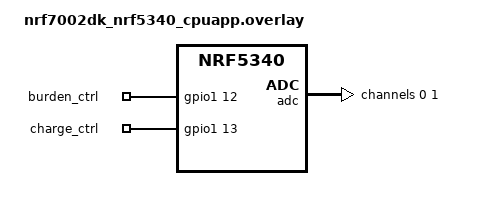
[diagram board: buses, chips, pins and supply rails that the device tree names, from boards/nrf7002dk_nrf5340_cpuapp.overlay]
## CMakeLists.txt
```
#
# Copyright (c) 2021 Nordic Semiconductor ASA
#
# SPDX-License-Identifier: LicenseRef-Nordic-5-Clause
#

cmake_minimum_required(VERSION 3.20.0)

# Set Kconfig root files that will be processed as a first Kconfig for used child images.
set(mcuboot_KCONFIG_ROOT "\\\${ZEPHYR_CONNECTEDHOMEIP_MODULE_DIR}/config/nrfconnect/chip-module/Kconfig.mcuboot.root")
set(multiprotocol_rpmsg_KCONFIG_ROOT "\\\${ZEPHYR_CONNECTEDHOMEIP_MODULE_DIR}/config/nrfconnect/chip-module/Kconfig.multiprotocol_rpmsg.root")
set(hci_rpmsg_KCONFIG_ROOT "\\\${ZEPHYR_CONNECTEDHOMEIP_MODULE_DIR}/config/nrfconnect/chip-module/Kconfig.hci_rpmsg.root")

# For prj.conf the CONF_FILE is empty. In other case extract the exact file name from the path string.
if(CONF_FILE)
    get_filename_component(CONFIG_FILE_NAME ${CONF_FILE} NAME)
endif()

if(NOT "${CONFIG_FILE_NAME}" STREQUAL "prj_no_dfu.conf")
    set(PM_STATIC_YML_FILE ${CMAKE_CURRENT_SOURCE_DIR}/configuration/${BOARD}/pm_static_dfu.yml)
endif()

find_package(Zephyr HINTS $ENV{ZEPHYR_BASE})

project(matter-template)

set(COMMON_ROOT ${ZEPHYR_NRF_MODULE_DIR}/samples/matter/common)
set(NLIO_ROOT ${ZEPHYR_CONNECTEDHOMEIP_MODULE_DIR}/third_party/nlio/repo)
include(${ZEPHYR_CONNECTEDHOMEIP_MODULE_DIR}/config/nrfconnect/app/enable-gnu-std.cmake)
include(${ZEPHYR_CONNECTEDHOMEIP_MODULE_DIR}/src/app/chip_data_model.cmake)

# NORDIC SDK APP START
target_include_directories(app PRIVATE
    src
    ${COMMON_ROOT}/src
    ${NLIO_ROOT}/include
    ${ZEPHYR_CONNECTEDHOMEIP_MODULE_DIR}/zzz_generated/app-common
)

target_sources(app PRIVATE
    src/app_task.cpp
    src/main.cpp
    src/adc.cpp
    src/burden_ctrl.cpp
    src/zcl_callbacks.cpp
    src/zap-generated/IMClusterCommandHandler.cpp
    src/zap-generated/callback-stub.cpp
    ${COMMON_ROOT}/src/led_widget.cpp
)

if(CONFIG_CHIP_OTA_REQUESTOR)
    target_sources(app PRIVATE ${COMMON_ROOT}/src/ota_util.cpp)
endif()

chip_configure_data_model(app
    INCLUDE_SERVER
    BYPASS_IDL
    GEN_DIR src/zap-generated
    ZAP_FILE ${CMAKE_CURRENT_SOURCE_DIR}/src/template.zap
)
# NORDIC SDK APP END
```

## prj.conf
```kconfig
# CPP
CONFIG_STD_CPP14=y

# Reduce application size
CONFIG_USE_SEGGER_RTT=n

# Add support for LEDs and buttons on Nordic development kits
CONFIG_DK_LIBRARY=y
CONFIG_PM_DEVICE=y

# GPIO support
CONFIG_GPIO=y
CONFIG_ADC=y

# Bluetooth Low Energy configuration
CONFIG_BT_DEVICE_NAME="MatterPwrSen"

# Other settings
CONFIG_MPU_STACK_GUARD=y
CONFIG_RESET_ON_FATAL_ERROR=n

# Disable NFC commissioning
CONFIG_CHIP_NFC_COMMISSIONING=n

# Enable Factory Data feature
CONFIG_CHIP_FACTORY_DATA=y
CONFIG_CHIP_FACTORY_DATA_BUILD=y

# Use Thread and Matter
CONFIG_THREAD_NAME=y
CONFIG_CHIP=y
CONFIG_CHIP_ENABLE_PAIRING_AUTOSTART=y
CONFIG_CHIP_PROJECT_CONFIG="src/chip_project_config.h"
CONFIG_CHIP_WIFI=n
CONFIG_ADD_MCUBOOT_MEDIATE_SIM_FLASH_DTS=y
CONFIG_OPENTHREAD_MTD_SED=y
CONFIG_OPENTHREAD_POLL_PERIOD=300000
CONFIG_NRF_CC3XX_PLATFORM=y
CONFIG_CHIP_PERSISTENT_SUBSCRIPTIONS=y
CONFIG_MATTER_LOG_LEVEL_INF=y
CONFIG_CHIP_LAST_FABRIC_REMOVED_ERASE_AND_PAIRING_START=y
CONFIG_CHIP_LIB_SHELL=y
```

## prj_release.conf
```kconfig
# CPP
CONFIG_STD_CPP14=y

# Reduce application size
CONFIG_USE_SEGGER_RTT=n

# Add support for LEDs and buttons on Nordic development kits
CONFIG_DK_LIBRARY=y
CONFIG_PM_DEVICE=y

# ADC support
CONFIG_ADC=y

# Bluetooth Low Energy configuration
CONFIG_BT_DEVICE_NAME="MatterPwrSen"

# Other settings
CONFIG_MPU_STACK_GUARD=y
CONFIG_RESET_ON_FATAL_ERROR=n

# Disable NFC commissioning
CONFIG_CHIP_NFC_COMMISSIONING=n

# Enable Factory Data feature
CONFIG_CHIP_FACTORY_DATA=y
CONFIG_CHIP_FACTORY_DATA_BUILD=y

# Use Thread and Matter
CONFIG_THREAD_NAME=y
CONFIG_CHIP=y
CONFIG_CHIP_ENABLE_PAIRING_AUTOSTART=y
CONFIG_CHIP_PROJECT_CONFIG="src/chip_project_config.h"
CONFIG_CHIP_WIFI=n
CONFIG_ADD_MCUBOOT_MEDIATE_SIM_FLASH_DTS=y
CONFIG_OPENTHREAD_MTD_SED=y
CONFIG_OPENTHREAD_POLL_PERIOD=300000
CONFIG_NRF_CC3XX_PLATFORM=y
CONFIG_CHIP_PERSISTENT_SUBSCRIPTIONS=y
CONFIG_CHIP_LAST_FABRIC_REMOVED_ERASE_AND_PAIRING_START=y

# Disable all debug features
CONFIG_USE_SEGGER_RTT=n
CONFIG_SHELL=n
CONFIG_OPENTHREAD_SHELL=n
CONFIG_CONSOLE=n
CONFIG_UART_CONSOLE=n
CONFIG_SERIAL=n
CONFIG_LOG=n
CONFIG_LOG_MODE_MINIMAL=n
CONFIG_ASSERT_VERBOSE=n
CONFIG_ASSERT_NO_FILE_INFO=y
CONFIG_PRINTK=n
CONFIG_PRINTK_SYNC=n
CONFIG_THREAD_NAME=n
CONFIG_BOOT_BANNER=n
```

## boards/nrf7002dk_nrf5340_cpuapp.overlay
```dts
/*
 * Copyright (c) 2021 Nordic Semiconductor ASA
 *
 * SPDX-License-Identifier: LicenseRef-Nordic-5-Clause
 */

#include <zephyr/dt-bindings/ipc_service/static_vrings.h>

/ {
	chosen {
		nordic,pm-ext-flash = &mx25r64;
	};
};

/* Set IPC thread priority to the highest value to not collide with other threads. */
&ipc0 {
	zephyr,priority = <0 PRIO_COOP>;
};

&adc {
	#address-cells = <1>;
	#size-cells = <0>;

	channel@0 {
		reg = <0>;
		zephyr,gain = "ADC_GAIN_1_4";
		zephyr,reference = "ADC_REF_INTERNAL";
		zephyr,acquisition-time = <ADC_ACQ_TIME_DEFAULT>;
		zephyr,input-positive = <NRF_SAADC_AIN0>;
		zephyr,resolution = <10>;
	};

	channel@1 {
		reg = <1>;
		zephyr,gain = "ADC_GAIN_1_4";
		zephyr,reference = "ADC_REF_INTERNAL";
		zephyr,acquisition-time = <ADC_ACQ_TIME_DEFAULT>;
		zephyr,input-positive = <NRF_SAADC_AIN1>;
		zephyr,resolution = <10>;
	};
};

/ {
	aliases {
		burden-ctrl = &burden_ctrl;	
		charge-ctrl = &charge_ctrl;
	};

	burden {
		compatible = "gpio-leds";

		burden_ctrl: burden_ctrl {
			gpios = <&gpio1 12 GPIO_ACTIVE_HIGH>; /* D10 */
		};
		charge_ctrl: charge_ctrl {
			gpios = <&gpio1 13 GPIO_ACTIVE_HIGH>; /* D11 */
		};
	};
};
```

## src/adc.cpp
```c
#include "adc.h"
#include <zephyr/drivers/adc.h>
#include <zephyr/logging/log.h>

#include "params.h"
#include "burden_ctrl.h"

LOG_MODULE_REGISTER(adc, CONFIG_CHIP_APP_LOG_LEVEL);

namespace adc
{
namespace
{
	const device *adc_dev = DEVICE_DT_GET(DT_NODELABEL(adc));
	constexpr adc_channel_cfg burden_cfg_dt = ADC_CHANNEL_CFG_DT(DT_CHILD(DT_NODELABEL(adc), channel_0));

	// device *adc_battery_dev = DEVICE_DT_GET(DT_NODELABEL(adc));
	constexpr adc_channel_cfg battery_cfg_dt = ADC_CHANNEL_CFG_DT(DT_CHILD(DT_NODELABEL(adc), channel_1));

	constexpr uint8_t ADC_RESOLUTION = 10;

} // namespace

bool Init()
{
    if (!burden::Init())
    {
        LOG_ERR("Failed to initialize burden controller");
        return false;
    }

	if (!device_is_ready(adc_dev)) {
		LOG_ERR("ADC device is not ready");
		return false;
	}

	int err = adc_channel_setup(adc_dev, &burden_cfg_dt);
	if (err) {
		LOG_ERR("Couldn't setup burden ADC");
		return false;
	}

	err = adc_channel_setup(adc_dev, &battery_cfg_dt);
	if (err) {
		LOG_ERR("Couldn't setup battery ADC");
		return false;
	}
	return true;
}

Measurement ReadBurdenVoltage()
{
	static int16_t buffer[1];
	static adc_sequence seq = { .channels = BIT(burden_cfg_dt.channel_id),
				    .buffer = buffer,
				    .buffer_size = sizeof(buffer),
				    .resolution = ADC_RESOLUTION };
	static int32_t adcVRef = adc_ref_internal(adc_dev);

	Measurement res;

    burden::SetMeasurementMode();
	int err = adc_read(adc_dev, &seq);
	if (err) {
		LOG_WRN("Failed to read burden ADC");
        burden::SetChargingMode();
		res.success = false;
		return res;
	}

	int32_t mV = buffer[0];
	err = adc_raw_to_millivolts(adcVRef, burden_cfg_dt.gain, ADC_RESOLUTION, &mV);
	if (err) {
		LOG_WRN("Failed to convert burden reading to mV");
        burden::SetChargingMode();
		res.success = false;
		return res;
	}
    burden::SetChargingMode();

	res.value = mV;
	res.success = true;

	return res;
}

Measurement ReadCapVoltage()
{
	static int16_t buffer[1];
	static adc_sequence seq = { .channels = BIT(battery_cfg_dt.channel_id),
				    .buffer = buffer,
				    .buffer_size = sizeof(buffer),
				    .resolution = ADC_RESOLUTION };
	static int32_t adcVRef = adc_ref_internal(adc_dev);

	Measurement res;

	int err = adc_read(adc_dev, &seq);
	if (err) {
		LOG_WRN("Failed to read cap ADC");
		res.success = false;
		return res;
	}

	int32_t mV = buffer[0];
	err = adc_raw_to_millivolts(adcVRef, battery_cfg_dt.gain, ADC_RESOLUTION, &mV);
	if (err) {
		LOG_WRN("Failed to convert cap reading to mV");
		res.success = false;
		return res;
	}

	res.value = mV;
	res.success = true;

	return res;
}
} // namespace adc
```

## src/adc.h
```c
#pragma once
#include <zephyr/drivers/adc.h>

namespace adc
{
struct Measurement {
	bool success;
	int32_t value;
};

bool Init();
Measurement ReadBurdenVoltage();
Measurement ReadCapVoltage();
} // namespace adc
```

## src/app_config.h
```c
/*
 * Copyright (c) 2022 Nordic Semiconductor ASA
 *
 * SPDX-License-Identifier: LicenseRef-Nordic-5-Clause
 */

#pragma once

#include "board_util.h"

#define FUNCTION_BUTTON DK_BTN1
#define FUNCTION_BUTTON_MASK DK_BTN1_MSK

#define SYSTEM_STATE_LED DK_LED1
#define FACTORY_RESET_SIGNAL_LED DK_LED2
```

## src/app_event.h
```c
/*
 * Copyright (c) 2021 Nordic Semiconductor ASA
 *
 * SPDX-License-Identifier: LicenseRef-Nordic-5-Clause
 */

#pragma once

#include <cstdint>

#include "event_types.h"

class LEDWidget;

enum class AppEventType : uint8_t {
	None = 0,
	Button,
	ButtonPushed,
	ButtonReleased,
	Timer,
	UpdateLedState,
	SensorActivate,
	SensorDeactivate,
	SensorMeasure
};

enum class FunctionEvent : uint8_t { NoneSelected = 0, FactoryReset };

struct AppEvent {
	union {
		struct {
			uint8_t PinNo;
			uint8_t Action;
		} ButtonEvent;
		struct {
			void *Context;
		} TimerEvent;
		struct {
			LEDWidget *LedWidget;
		} UpdateLedStateEvent;
	};

	AppEventType Type{ AppEventType::None };
	EventHandler Handler;
};
```

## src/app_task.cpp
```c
/*
 * Copyright (c) 2021 Nordic Semiconductor ASA
 *
 * SPDX-License-Identifier: LicenseRef-Nordic-5-Clause
 */

#include "app_task.h"
#include "app_config.h"
#include "fabric_table_delegate.h"
#include "led_util.h"

#include <platform/CHIPDeviceLayer.h>

#include "board_util.h"
#include <app-common/zap-generated/attributes/Accessors.h>
#include <app/CommandHandler.h>
#include <app/server/OnboardingCodesUtil.h>
#include <app/server/Server.h>
#include <credentials/DeviceAttestationCredsProvider.h>
#include <credentials/examples/DeviceAttestationCredsExample.h>
#include <lib/support/CHIPMem.h>
#include <lib/support/CodeUtils.h>
#include <system/SystemError.h>

#include "ota_util.h"

#include <dk_buttons_and_leds.h>
#include <zephyr/kernel.h>
#include <zephyr/logging/log.h>

#include "adc.h"
#include "conversions.h"
#include "params.h"
#include "rms.h"

LOG_MODULE_DECLARE(app, CONFIG_CHIP_APP_LOG_LEVEL);

using namespace ::chip;
using namespace ::chip::app;
using namespace ::chip::Credentials;
using namespace ::chip::DeviceLayer;

namespace
{
constexpr size_t kAppEventQueueSize = 10;
constexpr uint32_t kFactoryResetTriggerTimeout = 6000;

K_MSGQ_DEFINE(sAppEventQueue, sizeof(AppEvent), kAppEventQueueSize, alignof(AppEvent));
k_timer sFunctionTimer;
k_timer sSensorTimer;

LEDWidget sStatusLED;
FactoryResetLEDsWrapper<1> sFactoryResetLEDs{ { FACTORY_RESET_SIGNAL_LED } };

bool sIsNetworkProvisioned = false;
bool sIsNetworkEnabled = false;
bool sHaveBLEConnections = false;

RMS<RMS_MAX_SAMPLES> sRMSCurrent;
} // namespace

namespace LedConsts
{
namespace StatusLed
{
	namespace Unprovisioned
	{
		constexpr uint32_t kOn_ms{ 100 };
		constexpr uint32_t kOff_ms{ 1900 };
	} // namespace Unprovisioned
	namespace Provisioned
	{
		constexpr uint32_t kOn_ms{ 100 };
		constexpr uint32_t kOff_ms{ 900 };
	} // namespace Provisioned
	namespace ConnectedToFabric
	{
		constexpr bool kConnectedState = false;
	}
} // namespace StatusLed
} // namespace LedConsts

bool emberAfTimeSynchronizationClusterSetUtcTimeCallback(
	CommandHandler *commandObj, const ConcreteCommandPath &commandPath,
	const chip::app::Clusters::TimeSynchronization::Commands::SetUtcTime::DecodableType &commandData)
{
	return true;
}

CHIP_ERROR AppTask::Init()
{
	/* Initialize CHIP stack */
	LOG_INF("Init CHIP stack");

	CHIP_ERROR err = chip::Platform::MemoryInit();
	if (err != CHIP_NO_ERROR) {
		LOG_ERR("Platform::MemoryInit() failed");
		return err;
	}

	err = PlatformMgr().InitChipStack();
	if (err != CHIP_NO_ERROR) {
		LOG_ERR("PlatformMgr().InitChipStack() failed");
		return err;
	}

	err = ThreadStackMgr().InitThreadStack();
	if (err != CHIP_NO_ERROR) {
		LOG_ERR("ThreadStackMgr().InitThreadStack() failed: %s", ErrorStr(err));
		return err;
	}

	err = ConnectivityMgr().SetThreadDeviceType(ConnectivityManager::kThreadDeviceType_SleepyEndDevice);
	if (err != CHIP_NO_ERROR) {
		LOG_ERR("ConnectivityMgr().SetThreadDeviceType() failed: %s", ErrorStr(err));
		return err;
	}

	bool success = adc::Init();
	if (!success) {
		LOG_ERR("Failed to initialize ADC");
		return CHIP_ERROR_UNEXPECTED_EVENT;
	}

	/* Initialize LEDs */
	LEDWidget::InitGpio();
	LEDWidget::SetStateUpdateCallback(LEDStateUpdateHandler);

	sStatusLED.Init(SYSTEM_STATE_LED);

	UpdateStatusLED();

	/* Initialize buttons */
	int ret = dk_buttons_init(ButtonEventHandler);
	if (ret) {
		LOG_ERR("dk_buttons_init() failed");
		return chip::System::MapErrorZephyr(ret);
	}

	/* Initialize function timer */
	k_timer_init(&sFunctionTimer, &AppTask::FunctionTimerTimeoutCallback, nullptr);
	k_timer_user_data_set(&sFunctionTimer, this);

	/* Initialize sensor timer */
	k_timer_init(&sSensorTimer, &AppTask::SensorTimerHandler, nullptr);
	k_timer_user_data_set(&sSensorTimer, this);

	/* OTA image confirmation must be done before the factory data init. */
	OtaConfirmNewImage();

	/* Initialize CHIP server */
	ReturnErrorOnFailure(mFactoryDataProvider.Init());
	SetDeviceInstanceInfoProvider(&mFactoryDataProvider);
	SetDeviceAttestationCredentialsProvider(&mFactoryDataProvider);
	SetCommissionableDataProvider(&mFactoryDataProvider);

	static chip::CommonCaseDeviceServerInitParams initParams;
	(void)initParams.InitializeStaticResourcesBeforeServerInit();

	ReturnErrorOnFailure(chip::Server::GetInstance().Init(initParams));
	ConfigurationMgr().LogDeviceConfig();
	PrintOnboardingCodes(chip::RendezvousInformationFlags(chip::RendezvousInformationFlag::kBLE));
	AppFabricTableDelegate::Init();

	chip::app::Clusters::ElectricalMeasurement::Attributes::MeasurementType::Set(ENDPOINT_ID, 0b00000001);

	/*
	 * Add CHIP event handler and start CHIP thread.
	 * Note that all the initialization code should happen prior to this point to avoid data races
	 * between the main and the CHIP threads.
	 */
	PlatformMgr().AddEventHandler(ChipEventHandler, 0);

	err = PlatformMgr().StartEventLoopTask();
	if (err != CHIP_NO_ERROR) {
		LOG_ERR("PlatformMgr().StartEventLoopTask() failed");
		return err;
	}

	return CHIP_NO_ERROR;
}

CHIP_ERROR AppTask::StartApp()
{
	ReturnErrorOnFailure(Init());

	AppEvent event = {};

	while (true) {
		k_msgq_get(&sAppEventQueue, &event, K_FOREVER);
		DispatchEvent(event);
	}

	return CHIP_NO_ERROR;
}

void AppTask::SensorTimerHandler(k_timer *timer)
{
	AppEvent event;
	event.Type = AppEventType::SensorMeasure;
	event.Handler = AppTask::SensorMeasureHandler;
	AppTask::Instance().PostEvent(event);
}

void AppTask::StartSensorTimer(uint32_t aTimeoutMs)
{
	k_timer_start(&sSensorTimer, K_MSEC(aTimeoutMs), K_MSEC(aTimeoutMs));
}

void AppTask::StopSensorTimer()
{
	k_timer_stop(&sSensorTimer);
}

void AppTask::ButtonEventHandler(uint32_t buttonState, uint32_t hasChanged)
{
	AppEvent button_event;
	button_event.Type = AppEventType::Button;

	if (FUNCTION_BUTTON_MASK & hasChanged) {
		button_event.ButtonEvent.PinNo = FUNCTION_BUTTON;
		button_event.ButtonEvent.Action =
			static_cast<uint8_t>((FUNCTION_BUTTON_MASK & buttonState) ? AppEventType::ButtonPushed :
										    AppEventType::ButtonReleased);
		button_event.Handler = FunctionHandler;
		PostEvent(button_event);
	}
}

void AppTask::FunctionTimerTimeoutCallback(k_timer *timer)
{
	if (!timer) {
		return;
	}

	AppEvent event;
	event.Type = AppEventType::Timer;
	event.TimerEvent.Context = k_timer_user_data_get(timer);
	event.Handler = FunctionTimerEventHandler;
	PostEvent(event);
}

void AppTask::FunctionTimerEventHandler(const AppEvent &)
{
	if (Instance().mFunction == FunctionEvent::FactoryReset) {
		Instance().mFunction = FunctionEvent::NoneSelected;
		LOG_INF("Factory Reset triggered");

		sStatusLED.Set(true);
		sFactoryResetLEDs.Set(true);

		chip::Server::GetInstance().ScheduleFactoryReset();
	}
}

void AppTask::FunctionHandler(const AppEvent &event)
{
	if (event.ButtonEvent.PinNo != FUNCTION_BUTTON)
		return;

	if (event.ButtonEvent.Action == static_cast<uint8_t>(AppEventType::ButtonPushed)) {
		Instance().StartTimer(kFactoryResetTriggerTimeout);
		Instance().mFunction = FunctionEvent::FactoryReset;
	} else if (event.ButtonEvent.Action == static_cast<uint8_t>(AppEventType::ButtonReleased)) {
		if (Instance().mFunction == FunctionEvent::FactoryReset) {
			sFactoryResetLEDs.Set(false);
			UpdateStatusLED();
			Instance().CancelTimer();
			Instance().mFunction = FunctionEvent::NoneSelected;
			LOG_INF("Factory Reset has been Canceled");
		}
	}
}

void AppTask::SensorActivateHandler(const AppEvent &)
{
	sRMSCurrent.reset();
	StartSensorTimer(1000 / MAINS_FREQUENCY);
}

void AppTask::SensorDeactivateHandler(const AppEvent &)
{
	StopSensorTimer();
}

void AppTask::SensorMeasureHandler(const AppEvent &)
{
	constexpr float SQRT_2 = 1.41421356237;

	adc::Measurement currMeas = adc::ReadBurdenVoltage();
	float current = map(currMeas.value, MIN_BURDEN_VOLTAGE, MAX_BURDEN_VOLTAGE, MIN_CURR, MAX_CURR);
	if (current < 0) {
		current = 0;
	}
	current /= 1000; // To amps

	if (currMeas.success) {
		sRMSCurrent.addSample(current);
	}

	chip::app::Clusters::ElectricalMeasurement::Attributes::AcFrequency::Set(ENDPOINT_ID, MAINS_FREQUENCY);

	float v = MAINS_VOLTAGE / SQRT_2;
	chip::app::Clusters::ElectricalMeasurement::Attributes::RmsVoltage::Set(ENDPOINT_ID, v);
	
	if (sRMSCurrent.ready() && currMeas.success) {
		chip::app::Clusters::ElectricalMeasurement::Attributes::RmsCurrent::Set(
			ENDPOINT_ID, sRMSCurrent.read() * 1000); // To mA again
		chip::app::Clusters::ElectricalMeasurement::Attributes::ActivePower::Set(ENDPOINT_ID,
											 current * MAINS_VOLTAGE);
	}

	adc::Measurement batMeas = adc::ReadCapVoltage();
	int32_t bat = batMeas.value;
	if (bat < 0) {
		bat = 0;
	}

	if (batMeas.success) {
		chip::app::Clusters::PowerSource::Attributes::BatVoltage::Set(0, bat);
		chip::app::Clusters::PowerSource::Attributes::BatPercentRemaining::Set(
			0, ConvertBatteryVoltageToPercent(bat));
	}
}

void AppTask::LEDStateUpdateHandler(LEDWidget &ledWidget)
{
	AppEvent event;
	event.Type = AppEventType::UpdateLedState;
	event.Handler = UpdateLedStateEventHandler;
	event.UpdateLedStateEvent.LedWidget = &ledWidget;
	PostEvent(event);
}

void AppTask::UpdateLedStateEventHandler(const AppEvent &event)
{
	if (event.Type == AppEventType::UpdateLedState) {
		event.UpdateLedStateEvent.LedWidget->UpdateState();
	}
}

void AppTask::UpdateStatusLED()
{
	if (sIsNetworkProvisioned && sIsNetworkEnabled) {
		sStatusLED.Set(LedConsts::StatusLed::ConnectedToFabric::kConnectedState);
		LOG_INF("NetworkEnabledAndProvisoned");
	} else if (sHaveBLEConnections) {
		sStatusLED.Blink(LedConsts::StatusLed::Unprovisioned::kOn_ms,
				 LedConsts::StatusLed::Unprovisioned::kOff_ms);
		LOG_INF("UnProvisioned");
	} else {
		sStatusLED.Blink(LedConsts::StatusLed::Provisioned::kOn_ms, LedConsts::StatusLed::Provisioned::kOff_ms);
		LOG_INF("Provisioned");
	}
}

void AppTask::ChipEventHandler(const ChipDeviceEvent *event, intptr_t /* arg */)
{
	switch (event->Type) {
	case DeviceEventType::kCHIPoBLEAdvertisingChange:
		sHaveBLEConnections = ConnectivityMgr().NumBLEConnections() != 0;
		UpdateStatusLED();
		break;
	case DeviceEventType::kDnssdInitialized:
		InitBasicOTARequestor();
		break;
	case DeviceEventType::kThreadStateChange:
		sIsNetworkProvisioned = ConnectivityMgr().IsThreadProvisioned();
		sIsNetworkEnabled = ConnectivityMgr().IsThreadEnabled();
		UpdateStatusLED();
		break;
	default:
		break;
	}
}

void AppTask::CancelTimer()
{
	k_timer_stop(&sFunctionTimer);
}

void AppTask::StartTimer(uint32_t timeoutInMs)
{
	k_timer_start(&sFunctionTimer, K_MSEC(timeoutInMs), K_NO_WAIT);
}

void AppTask::PostEvent(const AppEvent &event)
{
	if (k_msgq_put(&sAppEventQueue, &event, K_NO_WAIT) != 0) {
		LOG_INF("Failed to post event to app task event queue");
	}
}

void AppTask::DispatchEvent(const AppEvent &event)
{
	if (event.Handler) {
		event.Handler(event);
	} else {
		LOG_INF("Event received with no handler. Dropping event.");
	}
}
```

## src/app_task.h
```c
/*
 * Copyright (c) 2021 Nordic Semiconductor ASA
 *
 * SPDX-License-Identifier: LicenseRef-Nordic-5-Clause
 */

#pragma once

#include "app_event.h"
#include "led_widget.h"

#include <platform/CHIPDeviceLayer.h>

#if CONFIG_CHIP_FACTORY_DATA
#include <platform/nrfconnect/FactoryDataProvider.h>
#else
#include <platform/nrfconnect/DeviceInstanceInfoProviderImpl.h>
#endif

struct k_timer;

class AppTask {
public:

	static AppTask &Instance()
	{
		static AppTask sAppTask;
		return sAppTask;
	};

	CHIP_ERROR StartApp();

	static void PostEvent(const AppEvent &event);

	static void SensorActivateHandler(const AppEvent&event);
	static void SensorDeactivateHandler(const AppEvent&event);
private:
	CHIP_ERROR Init();

	void CancelTimer();
	void StartTimer(uint32_t timeoutInMs);

	static void DispatchEvent(const AppEvent &event);
	static void UpdateLedStateEventHandler(const AppEvent &event);
	static void FunctionHandler(const AppEvent &event);
	static void FunctionTimerEventHandler(const AppEvent &event);

	static void SensorTimerHandler(k_timer *timer);
	static void StartSensorTimer(uint32_t aTimeoutMs);
	static void StopSensorTimer();

	static void SensorMeasureHandler(const AppEvent&event);

	static void ChipEventHandler(const chip::DeviceLayer::ChipDeviceEvent *event, intptr_t arg);
	static void ButtonEventHandler(uint32_t buttonState, uint32_t hasChanged);
	static void LEDStateUpdateHandler(LEDWidget &ledWidget);
	static void FunctionTimerTimeoutCallback(k_timer *timer);
	static void UpdateStatusLED();

	FunctionEvent mFunction = FunctionEvent::NoneSelected;
	bool mFunctionTimerActive = false;

#if CONFIG_CHIP_FACTORY_DATA
	chip::DeviceLayer::FactoryDataProvider<chip::DeviceLayer::InternalFlashFactoryData> mFactoryDataProvider;
#endif
};
```

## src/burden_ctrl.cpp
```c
#include "burden_ctrl.h"

#include <zephyr/drivers/gpio.h>
#include <zephyr/logging/log.h>

LOG_MODULE_REGISTER(burden, CONFIG_CHIP_APP_LOG_LEVEL);

namespace burden
{

namespace
{
	constexpr gpio_dt_spec burden_ctrl_gpio_dt = GPIO_DT_SPEC_GET(DT_ALIAS(burden_ctrl), gpios);
    constexpr gpio_dt_spec charge_ctrl_gpio_dt = GPIO_DT_SPEC_GET(DT_ALIAS(burden_ctrl), gpios);
} // namespace

bool Init()
{
	if (!gpio_is_ready_dt(&burden_ctrl_gpio_dt)) {
		LOG_ERR("Failed to initialize burden GPIO");
		return false;
	}

	if (!gpio_is_ready_dt(&charge_ctrl_gpio_dt)) {
		LOG_ERR("Failed to initialize charge GPIO");
		return false;
	}

	int err = gpio_pin_configure_dt(&burden_ctrl_gpio_dt, GPIO_OUTPUT);
	if (err) {
		LOG_ERR("Failed to configure burden gpio");
		return false;
	}

	err = gpio_pin_configure_dt(&charge_ctrl_gpio_dt, GPIO_OUTPUT);
	if (err) {
		LOG_ERR("Failed to configure burden gpio");
		return false;
	}

	return true;
}

bool SetMeasurementMode()
{
	int err = gpio_pin_set(charge_ctrl_gpio_dt.port, charge_ctrl_gpio_dt.pin, 1);
	if (err) {
		LOG_ERR("Failed to set charge pin");
		return false;
	}

	err = gpio_pin_set(burden_ctrl_gpio_dt.port, burden_ctrl_gpio_dt.pin, 0);
	if (err) {
		LOG_ERR("Failed to set burden pin");
		return false;
	}
	return true;
}

bool SetChargingMode()
{
	int err = gpio_pin_set(charge_ctrl_gpio_dt.port, charge_ctrl_gpio_dt.pin, 0);
	if (err) {
		LOG_ERR("Failed to set charge pin");
		return false;
	}

	err = gpio_pin_set(burden_ctrl_gpio_dt.port, burden_ctrl_gpio_dt.pin, 1);
	if (err) {
		LOG_ERR("Failed to set burden pin");
		return false;
	}
	return true;
}
} // namespace burden
```

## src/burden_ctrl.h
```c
#pragma once

namespace burden {
    bool Init();
    bool SetMeasurementMode();
    bool SetChargingMode();
}
```

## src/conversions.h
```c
#pragma once
#include "params.h"

int32_t ConvertBatteryVoltageToPercent(int32_t mV)
{
	int32_t res = (100 * (mV - MIN_BATTERY_VOLTAGE)) / MAX_BATTERY_VOLTAGE;
	if (res < 0) {
		res = 0;
	}
	if (res > 100) {
		res = 100;
	}
	return res;
}

float map(float x, float in_min, float in_max, float out_min, float out_max)
{
  return (x - in_min) * (out_max - out_min) / (in_max - in_min) + out_min;
}
```

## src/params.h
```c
#pragma once
#include <cstdint>

constexpr uint8_t ENDPOINT_ID = 1;

constexpr int32_t PARAM_DIVISOR = 1000;

constexpr uint8_t RMS_MAX_SAMPLES = 50;

constexpr int32_t MAINS_VOLTAGE = (230 * 1000); // mV
constexpr int32_t MAINS_FREQUENCY = 50; // Hz

constexpr int32_t MIN_CURR = 0; // mA
constexpr int32_t MAX_CURR = 800; // mA
constexpr int32_t BURDE_VALUE = 100; // mOhm

constexpr int32_t MIN_BURDEN_VOLTAGE = 0; // mV stop measure here due to critical voltage
constexpr int32_t MAX_BURDEN_VOLTAGE = 3000; // mV

constexpr int32_t MIN_BATTERY_VOLTAGE = 2100; // mV stop measure here due to critical voltage
constexpr int32_t MAX_BATTERY_VOLTAGE = 3000; // mV
```

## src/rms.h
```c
#pragma once
#include <cmath>
#include <cstdint>
#include <numeric>

template <uint8_t bufSize> class RMS {
	float buf[bufSize] = { 0 };
	uint8_t bufCntr = 0;
	bool readyToPublish = false;

public:
	void addSample(float reading)
	{
		buf[bufCntr] = reading * reading;
		if (bufCntr >= bufSize) {
			readyToPublish = true;
			bufCntr = 0;
		}
	}

	float read()
	{
		float sum = std::accumulate(buf, buf + bufSize, 0) / static_cast<float>(bufSize);
		return sqrt(sum);
	}

	bool ready() { return readyToPublish; }

	void reset()
	{
		readyToPublish = false;
		bufCntr = 0;
	}
};
```
